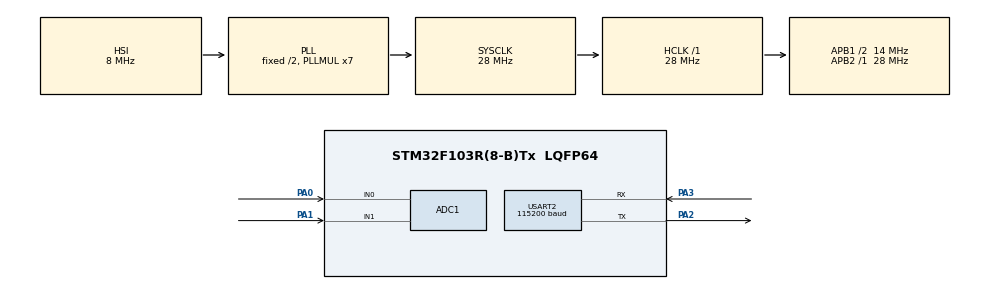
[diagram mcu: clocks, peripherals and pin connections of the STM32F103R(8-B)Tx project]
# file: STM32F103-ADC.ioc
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ADC1.Channel-0\#ChannelRegularConversion=ADC_CHANNEL_1
ADC1.Channel-1\#ChannelRegularConversion=ADC_CHANNEL_1
ADC1.ContinuousConvMode=ENABLE
ADC1.NbrOfConversion=2
ADC1.NbrOfConversionFlag=1
ADC1.Rank-0\#ChannelRegularConversion=1
ADC1.Rank-1\#ChannelRegularConversion=2
ADC1.SamplingTime-0\#ChannelRegularConversion=ADC_SAMPLETIME_1CYCLE_5
ADC1.SamplingTime-1\#ChannelRegularConversion=ADC_SAMPLETIME_1CYCLE_5
ADC1.master=1
Mcu.Family=STM32F1
Mcu.Name=STM32F103R(8-B)Tx
Mcu.Package=LQFP64
NVIC.ADC1_2_IRQn=true\:0\:0\:false\:false\:true\:true\:true\:true
NVIC.PriorityGroup=NVIC_PRIORITYGROUP_4
PA0-WKUP.Signal=ADCx_IN0
PA1.Signal=ADCx_IN1
PA13.GPIO_Label=TMS
PA13.Mode=Serial_Wire
PA13.Signal=SYS_JTMS-SWDIO
PA14.GPIO_Label=TCK
PA14.Mode=Serial_Wire
PA14.Signal=SYS_JTCK-SWCLK
PA2.Mode=Asynchronous
PA2.Signal=USART2_TX
PA3.Mode=Asynchronous
PA3.Signal=USART2_RX
PB3.GPIO_Label=SWO
PB3.Signal=SYS_JTDO-TRACESWO
PC14-OSC32_IN.Mode=LSE-External-Oscillator
PC14-OSC32_IN.Signal=RCC_OSC32_IN
PC15-OSC32_OUT.Mode=LSE-External-Oscillator
PC15-OSC32_OUT.Signal=RCC_OSC32_OUT
PD0-OSC_IN.Mode=HSE-External-Clock-Source
PD0-OSC_IN.Signal=RCC_OSC_IN
PD1-OSC_OUT.Mode=HSE-External-Clock-Source
PD1-OSC_OUT.Signal=RCC_OSC_OUT
ProjectManager.HeapSize=0x200
ProjectManager.StackSize=0x400
ProjectManager.TargetToolchain=STM32CubeIDE
RCC.AHBFreq_Value=28000000
RCC.APB1CLKDivider=RCC_HCLK_DIV2
RCC.APB1Freq_Value=14000000
RCC.APB1TimFreq_Value=28000000
RCC.APB2Freq_Value=28000000
RCC.APB2TimFreq_Value=28000000
RCC.HCLKFreq_Value=28000000
RCC.PLLMUL=RCC_PLL_MUL7
RCC.RTCClockSelection=RCC_RTCCLKSOURCE_LSE
RCC.SYSCLKFreq_VALUE=28000000
RCC.SYSCLKSource=RCC_SYSCLKSOURCE_PLLCLK
RCC.USBFreq_Value=28000000
SH.ADCx_IN0.0=ADC1_IN0,IN0
SH.ADCx_IN1.0=ADC1_IN1,IN1
USART2.BaudRate=115200
USART2.VirtualMode=VM_ASYNC
board=NUCLEO-F103RB

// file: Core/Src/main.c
/* USER CODE BEGIN Header */
/**
  ******************************************************************************
  * @file           : main.c
  * @brief          : Main program body
  ******************************************************************************
  * @attention
  *
  * Copyright (c) 2023 STMicroelectronics.
  * All rights reserved.
  *
  * This software is licensed under terms that can be found in the LICENSE file
  * in the root directory of this software component.
  * If no LICENSE file comes with this software, it is provided AS-IS.
  *
  ******************************************************************************
  */
/* USER CODE END Header */
#include "main.h"

/* USER CODE BEGIN Includes */
#include "stdio.h"
#include "string.h"
/* USER CODE END Includes */

ADC_HandleTypeDef hadc1;

UART_HandleTypeDef huart2;

char uart_buf[100];
int uart_buf_len;
int sample_counter = 0;

#define MAX_SAMPLES (50)
uint16_t adc_buff[MAX_SAMPLES];

static volatile uint8_t uart_send;

void SystemClock_Config(void);
static void MX_GPIO_Init(void);
static void MX_ADC1_Init(void);
static void MX_USART2_UART_Init(void);

/* USER CODE BEGIN 0 */
/**
  * @brief  Conversion complete callback in non blocking mode
  * @param  hadc: ADC handle
  * @retval None
  */
void HAL_ADC_ConvCpltCallback(ADC_HandleTypeDef* hadc)
{
  /* Prevent unused argument(s) compilation warning */
  UNUSED(hadc);
  if(uart_send == 1) return;

  uint16_t value = HAL_ADC_GetValue(hadc); // get ADC value
  adc_buff[sample_counter++] = value;
  if(sample_counter == MAX_SAMPLES){
	  uart_send = 1;
	  sample_counter = 0;
  }

  /* NOTE : This function should not be modified. When the callback is needed,
            function HAL_ADC_ConvCpltCallback must be implemented in the user file.
  //Flag za konverzijo
   */
}
/* USER CODE END 0 */
static uint32_t hal_errs;
static void send_adc_buffer(void)
{
	char buffer[10]; // create a buffer to hold the value as a string
	const int ref = 4095;

	for(int i = 0; i < MAX_SAMPLES;++i){
		// convert the value to a string and store it in the buffer
		float val = 3.3 * adc_buff[i] / 4095.f;

		sprintf(buffer, "%f\r\n", val);

		// send the value over UART using the HAL_UART_Transmit function
		if(HAL_UART_Transmit(&huart2, (uint8_t*)buffer, strlen(buffer), 5) != HAL_OK)	{
			hal_errs++;
		}
	}
}

int main(void)
{

  /* MCU Configuration--------------------------------------------------------*/

  /* Reset of all peripherals, Initializes the Flash interface and the Systick. */
  HAL_Init();

  /* Configure the system clock */
  SystemClock_Config();

  /* Initialize all configured peripherals */
  MX_GPIO_Init();
  MX_ADC1_Init();
  MX_USART2_UART_Init();
  /* USER CODE BEGIN 2 */
  HAL_ADCEx_Calibration_Start(&hadc1);
  HAL_ADC_Start_IT(&hadc1);
  //uart_buf_len = sprintf(uart_buf, "Hello\r\n");
  /* USER CODE END 2 */

  /* Infinite loop */
  while (1)
  {
	if(uart_send == 1){
		send_adc_buffer();
		uart_send = 0;
	}

  }
}

void SystemClock_Config(void)
{
  RCC_OscInitTypeDef RCC_OscInitStruct = {0};
  RCC_ClkInitTypeDef RCC_ClkInitStruct = {0};
  RCC_PeriphCLKInitTypeDef PeriphClkInit = {0};

  /** Initializes the RCC Oscillators according to the specified parameters
  * in the RCC_OscInitTypeDef structure.
  */
  RCC_OscInitStruct.OscillatorType = RCC_OSCILLATORTYPE_HSI;
  RCC_OscInitStruct.HSIState = RCC_HSI_ON;
  RCC_OscInitStruct.HSICalibrationValue = RCC_HSICALIBRATION_DEFAULT;
  RCC_OscInitStruct.PLL.PLLState = RCC_PLL_ON;
  RCC_OscInitStruct.PLL.PLLSource = RCC_PLLSOURCE_HSI_DIV2;
  RCC_OscInitStruct.PLL.PLLMUL = RCC_PLL_MUL7;
  if (HAL_RCC_OscConfig(&RCC_OscInitStruct) != HAL_OK)
  {
    Error_Handler();
  }

  /** Initializes the CPU, AHB and APB buses clocks
  */
  RCC_ClkInitStruct.ClockType = RCC_CLOCKTYPE_HCLK|RCC_CLOCKTYPE_SYSCLK
                              |RCC_CLOCKTYPE_PCLK1|RCC_CLOCKTYPE_PCLK2;
  RCC_ClkInitStruct.SYSCLKSource = RCC_SYSCLKSOURCE_PLLCLK;
  RCC_ClkInitStruct.AHBCLKDivider = RCC_SYSCLK_DIV1;
  RCC_ClkInitStruct.APB1CLKDivider = RCC_HCLK_DIV2;
  RCC_ClkInitStruct.APB2CLKDivider = RCC_HCLK_DIV1;

  if (HAL_RCC_ClockConfig(&RCC_ClkInitStruct, FLASH_LATENCY_1) != HAL_OK)
  {
    Error_Handler();
  }
  PeriphClkInit.PeriphClockSelection = RCC_PERIPHCLK_ADC;
  PeriphClkInit.AdcClockSelection = RCC_ADCPCLK2_DIV2;
  if (HAL_RCCEx_PeriphCLKConfig(&PeriphClkInit) != HAL_OK)
  {
    Error_Handler();
  }
}

static void MX_ADC1_Init(void)
{

  ADC_ChannelConfTypeDef sConfig = {0};

  /** Common config
  */
  hadc1.Instance = ADC1;
  hadc1.Init.ScanConvMode = ADC_SCAN_ENABLE;
  hadc1.Init.ContinuousConvMode = ENABLE;
  hadc1.Init.DiscontinuousConvMode = DISABLE;
  hadc1.Init.ExternalTrigConv = ADC_SOFTWARE_START;
  hadc1.Init.DataAlign = ADC_DATAALIGN_RIGHT;
  hadc1.Init.NbrOfConversion = 2;
  if (HAL_ADC_Init(&hadc1) != HAL_OK)
  {
    Error_Handler();
  }

  /** Configure Regular Channel
  */
  sConfig.Channel = ADC_CHANNEL_1;
  sConfig.Rank = ADC_REGULAR_RANK_1;
  sConfig.SamplingTime = ADC_SAMPLETIME_239CYCLES_5; // vedno je hodil noter
  if (HAL_ADC_ConfigChannel(&hadc1, &sConfig) != HAL_OK)
  {
    Error_Handler();
  }

  /** Configure Regular Channel
  */
  sConfig.Rank = ADC_REGULAR_RANK_2;
  if (HAL_ADC_ConfigChannel(&hadc1, &sConfig) != HAL_OK)
  {
    Error_Handler();
  }

}

static void MX_USART2_UART_Init(void)
{

  huart2.Instance = USART2;
  huart2.Init.BaudRate = 115200;
  huart2.Init.WordLength = UART_WORDLENGTH_8B;
  huart2.Init.StopBits = UART_STOPBITS_1;
  huart2.Init.Parity = UART_PARITY_NONE;
  huart2.Init.Mode = UART_MODE_TX_RX;
  huart2.Init.HwFlowCtl = UART_HWCONTROL_NONE;
  huart2.Init.OverSampling = UART_OVERSAMPLING_16;
  if (HAL_UART_Init(&huart2) != HAL_OK)
  {
    Error_Handler();
  }

}

static void MX_GPIO_Init(void)
{

  /* GPIO Ports Clock Enable */
  __HAL_RCC_GPIOC_CLK_ENABLE();
  __HAL_RCC_GPIOD_CLK_ENABLE();
  __HAL_RCC_GPIOA_CLK_ENABLE();
  __HAL_RCC_GPIOB_CLK_ENABLE();

}

void Error_Handler(void)
{
  __disable_irq();
  while (1)
  {
  }
}
